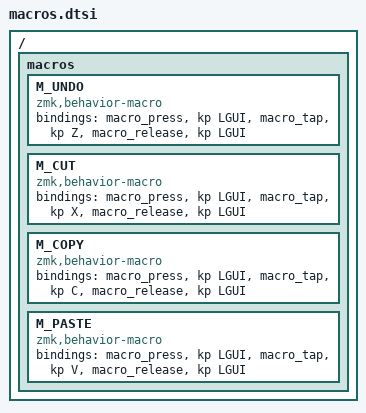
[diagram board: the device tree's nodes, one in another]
/ {
    macros {
        M_UNDO: M_UNDO {
            compatible = "zmk,behavior-macro";
            #binding-cells = <0>;
            bindings =
                <&macro_press>,
                <&kp LGUI>,
                <&macro_tap>,
                <&kp Z>,
                <&macro_release>,
                <&kp LGUI>;
        };

        M_CUT: M_CUT {
            compatible = "zmk,behavior-macro";
            #binding-cells = <0>;
            bindings =
                <&macro_press>,
                <&kp LGUI>,
                <&macro_tap>,
                <&kp X>,
                <&macro_release>,
                <&kp LGUI>;
        };

        M_COPY: M_COPY {
            compatible = "zmk,behavior-macro";
            #binding-cells = <0>;
            bindings =
                <&macro_press>,
                <&kp LGUI>,
                <&macro_tap>,
                <&kp C>,
                <&macro_release>,
                <&kp LGUI>;
        };

        M_PASTE: M_PASTE {
            compatible = "zmk,behavior-macro";
            #binding-cells = <0>;
            bindings =
                <&macro_press>,
                <&kp LGUI>,
                <&macro_tap>,
                <&kp V>,
                <&macro_release>,
                <&kp LGUI>;
        };
    };
};
